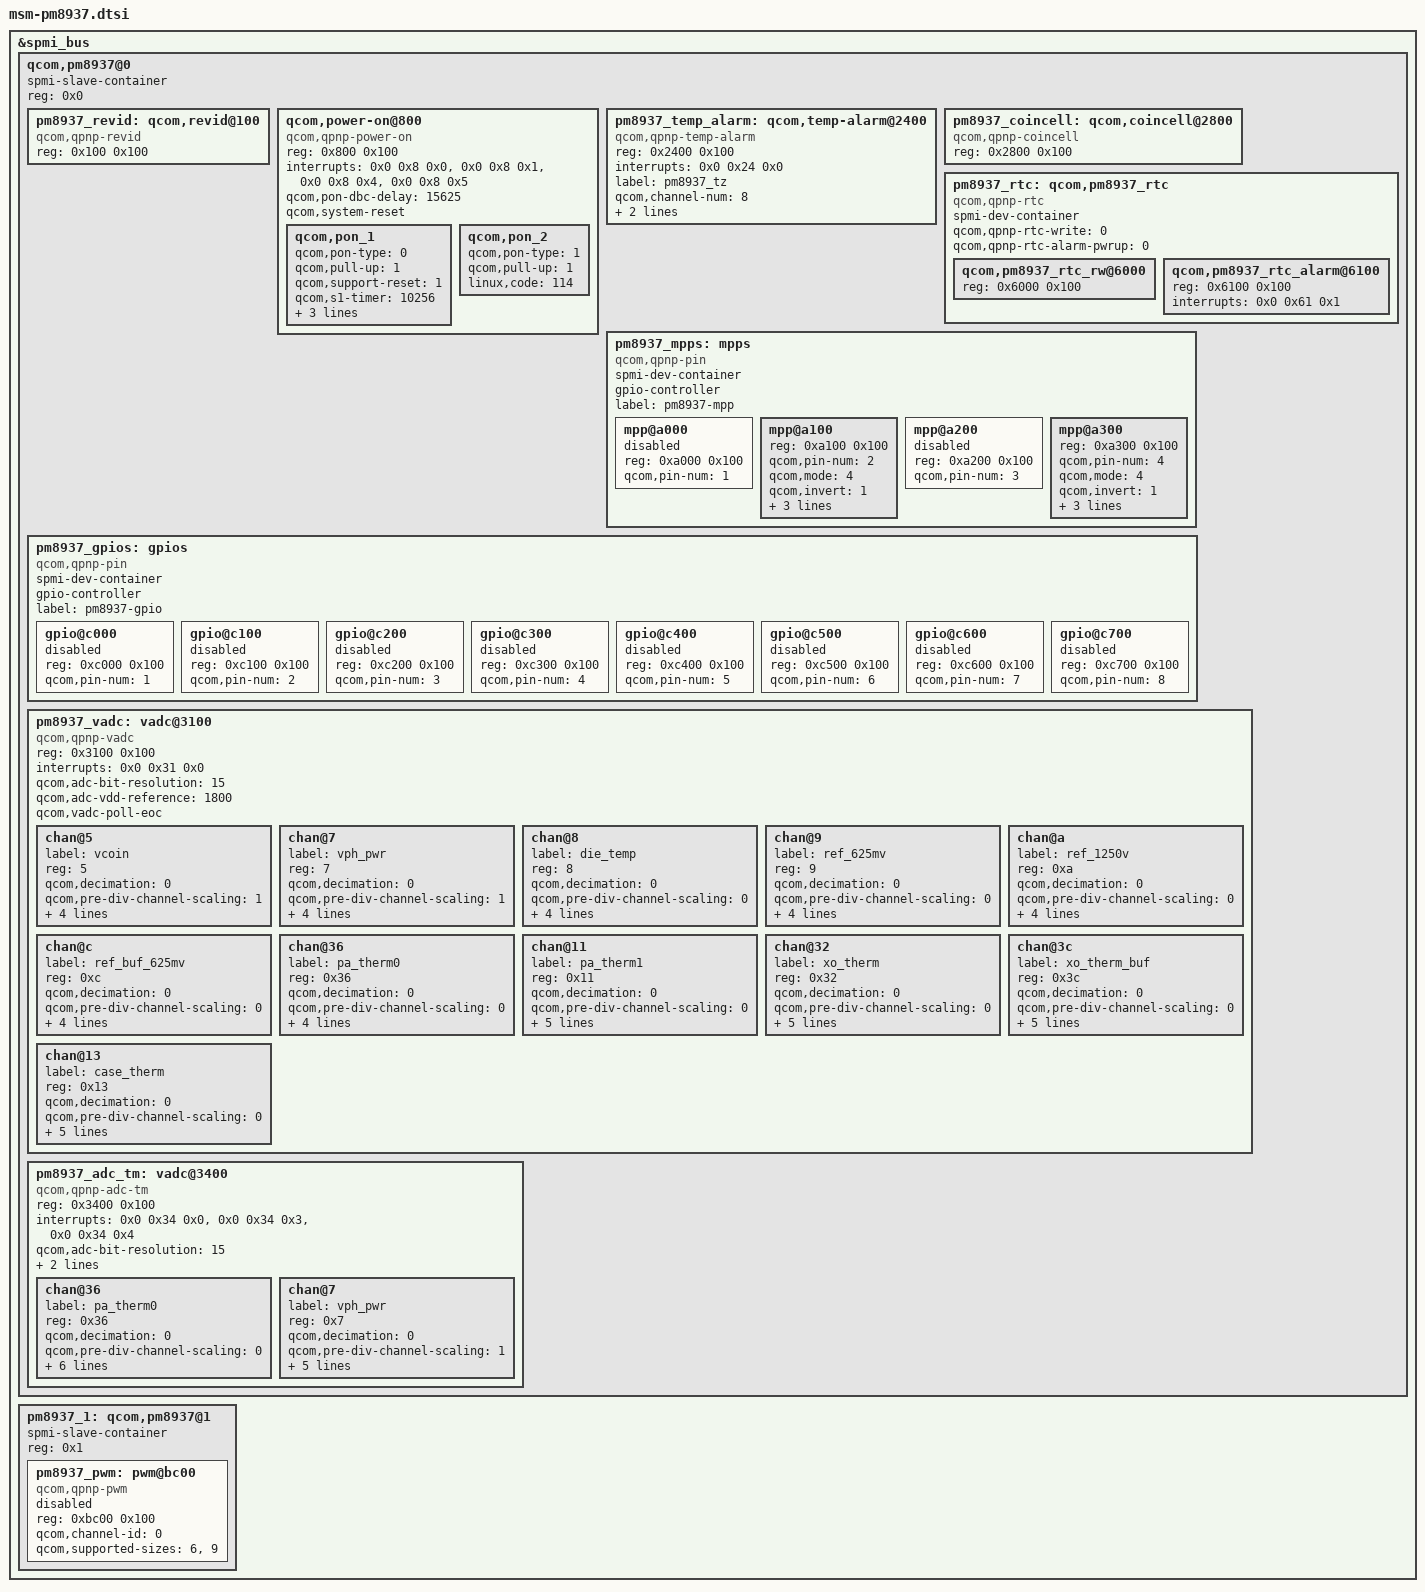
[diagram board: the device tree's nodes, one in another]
/*
 * Copyright (c) 2015-2016, The Linux Foundation. All rights reserved.
 *
 * This program is free software; you can redistribute it and/or modify
 * it under the terms of the GNU General Public License version 2 and
 * only version 2 as published by the Free Software Foundation.
 *
 * This program is distributed in the hope that it will be useful,
 * but WITHOUT ANY WARRANTY; without even the implied warranty of
 * MERCHANTABILITY or FITNESS FOR A PARTICULAR PURPOSE.  See the
 * GNU General Public License for more details.
 */

&spmi_bus {

	qcom,pm8937@0 {
		spmi-slave-container;
		reg = <0x0>;
		#address-cells = <1>;
		#size-cells = <1>;

		pm8937_revid: qcom,revid@100 {
			compatible = "qcom,qpnp-revid";
			reg = <0x100 0x100>;
		};

		qcom,power-on@800 {
			compatible = "qcom,qpnp-power-on";
			reg = <0x800 0x100>;
			interrupts = <0x0 0x8 0x0>,
				<0x0 0x8 0x1>,
				<0x0 0x8 0x4>,
				<0x0 0x8 0x5>;
			interrupt-names = "kpdpwr", "resin",
				"resin-bark", "kpdpwr-resin-bark";
			qcom,pon-dbc-delay = <15625>;
			qcom,system-reset;

			qcom,pon_1 {
				qcom,pon-type = <0>;
				qcom,pull-up = <1>;
				qcom,support-reset = <1>;
				qcom,s1-timer = <10256>;
				qcom,s2-timer = <2000>;
				qcom,s2-type = <7>;
				linux,code = <116>;
			};

			qcom,pon_2 {
				qcom,pon-type = <1>;
				qcom,pull-up = <1>;
				linux,code = <114>;
			};
		};

		pm8937_temp_alarm: qcom,temp-alarm@2400 {
			compatible = "qcom,qpnp-temp-alarm";
			reg = <0x2400 0x100>;
			interrupts = <0x0 0x24 0x0>;
			label = "pm8937_tz";
			qcom,channel-num = <8>;
			qcom,threshold-set = <0>;
			qcom,temp_alarm-vadc = <&pm8937_vadc>;
		};

		pm8937_coincell: qcom,coincell@2800 {
			compatible = "qcom,qpnp-coincell";
			reg = <0x2800 0x100>;
		};

		pm8937_rtc: qcom,pm8937_rtc {
			spmi-dev-container;
			compatible = "qcom,qpnp-rtc";
			#address-cells = <1>;
			#size-cells = <1>;
			qcom,qpnp-rtc-write = <0>;
			qcom,qpnp-rtc-alarm-pwrup = <0>;

			qcom,pm8937_rtc_rw@6000 {
				reg = <0x6000 0x100>;
			};

			qcom,pm8937_rtc_alarm@6100 {
				reg = <0x6100 0x100>;
				interrupts = <0x0 0x61 0x1>;
			};
		};

		pm8937_mpps: mpps {
			compatible = "qcom,qpnp-pin";
			spmi-dev-container;
			gpio-controller;
			#gpio-cells = <2>;
			#address-cells = <1>;
			#size-cells = <1>;
			label = "pm8937-mpp";

			mpp@a000 {
				reg = <0xa000 0x100>;
				qcom,pin-num = <1>;
				status = "disabled";
			};

			mpp@a100 {
				/* MPP2 - PA_THERM config */
				reg = <0xa100 0x100>;
				qcom,pin-num = <2>;
				qcom,mode = <4>; /* AIN input */
				qcom,invert = <1>; /* Enable MPP */
				qcom,ain-route = <1>; /* AMUX 6 */
				qcom,master-en = <1>;
				qcom,src-sel = <0>; /* Function constant */
			};

			mpp@a200 {
				reg = <0xa200 0x100>;
				qcom,pin-num = <3>;
				status = "disabled";
			};

			mpp@a300 {
				/* MPP4 - CASE_THERM config */
				reg = <0xa300 0x100>;
				qcom,pin-num = <4>;
				qcom,mode = <4>; /* AIN input */
				qcom,invert = <1>; /* Enable MPP */
				qcom,ain-route = <3>; /* AMUX 8 */
				qcom,master-en = <1>;
				qcom,src-sel = <0>; /* Function constant */
			};
		};

		pm8937_gpios: gpios {
			spmi-dev-container;
			compatible = "qcom,qpnp-pin";
			gpio-controller;
			#gpio-cells = <2>;
			#address-cells = <1>;
			#size-cells = <1>;
			label = "pm8937-gpio";

			gpio@c000 {
				reg = <0xc000 0x100>;
				qcom,pin-num = <1>;
				status = "disabled";
			};

			gpio@c100 {
				reg = <0xc100 0x100>;
				qcom,pin-num = <2>;
				status = "disabled";
			};

			gpio@c200 {
				reg = <0xc200 0x100>;
				qcom,pin-num = <3>;
				status = "disabled";
			};

			gpio@c300 {
				reg = <0xc300 0x100>;
				qcom,pin-num = <4>;
				status = "disabled";
			};

			gpio@c400 {
				reg = <0xc400 0x100>;
				qcom,pin-num = <5>;
				status = "disabled";
			};

			gpio@c500 {
				reg = <0xc500 0x100>;
				qcom,pin-num = <6>;
				status = "disabled";
			};

			gpio@c600 {
				reg = <0xc600 0x100>;
				qcom,pin-num = <7>;
				status = "disabled";
			};

			gpio@c700 {
				reg = <0xc700 0x100>;
				qcom,pin-num = <8>;
				status = "disabled";
			};
		};

		pm8937_vadc: vadc@3100 {
			compatible = "qcom,qpnp-vadc";
			reg = <0x3100 0x100>;
			#address-cells = <1>;
			#size-cells = <0>;
			interrupts = <0x0 0x31 0x0>;
			interrupt-names = "eoc-int-en-set";
			qcom,adc-bit-resolution = <15>;
			qcom,adc-vdd-reference = <1800>;
			qcom,vadc-poll-eoc;

			chan@5 {
				label = "vcoin";
				reg = <5>;
				qcom,decimation = <0>;
				qcom,pre-div-channel-scaling = <1>;
				qcom,calibration-type = "absolute";
				qcom,scale-function = <0>;
				qcom,hw-settle-time = <0>;
				qcom,fast-avg-setup = <0>;
			};

			chan@7 {
				label = "vph_pwr";
				reg = <7>;
				qcom,decimation = <0>;
				qcom,pre-div-channel-scaling = <1>;
				qcom,calibration-type = "absolute";
				qcom,scale-function = <0>;
				qcom,hw-settle-time = <0>;
				qcom,fast-avg-setup = <0>;
			};

			chan@8 {
				label = "die_temp";
				reg = <8>;
				qcom,decimation = <0>;
				qcom,pre-div-channel-scaling = <0>;
				qcom,calibration-type = "absolute";
				qcom,scale-function = <3>;
				qcom,hw-settle-time = <0>;
				qcom,fast-avg-setup = <0>;
			};

			chan@9 {
				label = "ref_625mv";
				reg = <9>;
				qcom,decimation = <0>;
				qcom,pre-div-channel-scaling = <0>;
				qcom,calibration-type = "absolute";
				qcom,scale-function = <0>;
				qcom,hw-settle-time = <0>;
				qcom,fast-avg-setup = <0>;
			};

			chan@a {
				label = "ref_1250v";
				reg = <0xa>;
				qcom,decimation = <0>;
				qcom,pre-div-channel-scaling = <0>;
				qcom,calibration-type = "absolute";
				qcom,scale-function = <0>;
				qcom,hw-settle-time = <0>;
				qcom,fast-avg-setup = <0>;
			};

			chan@c {
				label = "ref_buf_625mv";
				reg = <0xc>;
				qcom,decimation = <0>;
				qcom,pre-div-channel-scaling = <0>;
				qcom,calibration-type = "absolute";
				qcom,scale-function = <0>;
				qcom,hw-settle-time = <0>;
				qcom,fast-avg-setup = <0>;
			};

			chan@36 {
				label = "pa_therm0";
				reg = <0x36>;
				qcom,decimation = <0>;
				qcom,pre-div-channel-scaling = <0>;
				qcom,calibration-type = "ratiometric";
				qcom,scale-function = <2>;
				qcom,hw-settle-time = <2>;
				qcom,fast-avg-setup = <0>;
			};

			chan@11 {
				label = "pa_therm1";
				reg = <0x11>;
				qcom,decimation = <0>;
				qcom,pre-div-channel-scaling = <0>;
				qcom,calibration-type = "ratiometric";
				qcom,scale-function = <2>;
				qcom,hw-settle-time = <2>;
				qcom,fast-avg-setup = <0>;
				qcom,vadc-thermal-node;
			};

			chan@32 {
				label = "xo_therm";
				reg = <0x32>;
				qcom,decimation = <0>;
				qcom,pre-div-channel-scaling = <0>;
				qcom,calibration-type = "ratiometric";
				qcom,scale-function = <4>;
				qcom,hw-settle-time = <2>;
				qcom,fast-avg-setup = <0>;
				qcom,vadc-thermal-node;
			};

			chan@3c {
				label = "xo_therm_buf";
				reg = <0x3c>;
				qcom,decimation = <0>;
				qcom,pre-div-channel-scaling = <0>;
				qcom,calibration-type = "ratiometric";
				qcom,scale-function = <4>;
				qcom,hw-settle-time = <2>;
				qcom,fast-avg-setup = <0>;
				qcom,vadc-thermal-node;
			};

			chan@13 {
				label = "case_therm";
				reg = <0x13>;
				qcom,decimation = <0>;
				qcom,pre-div-channel-scaling = <0>;
				qcom,calibration-type = "ratiometric";
				qcom,scale-function = <2>;
				qcom,hw-settle-time = <2>;
				qcom,fast-avg-setup = <0>;
				qcom,vadc-thermal-node;
			};
		};

		pm8937_adc_tm: vadc@3400 {
			compatible = "qcom,qpnp-adc-tm";
			reg = <0x3400 0x100>;
			#address-cells = <1>;
			#size-cells = <0>;
			interrupts =	<0x0 0x34 0x0>,
					<0x0 0x34 0x3>,
					<0x0 0x34 0x4>;
			interrupt-names =	"eoc-int-en-set",
						"high-thr-en-set",
						"low-thr-en-set";
			qcom,adc-bit-resolution = <15>;
			qcom,adc-vdd-reference = <1800>;
			qcom,adc_tm-vadc = <&pm8937_vadc>;

			chan@36 {
				label = "pa_therm0";
				reg = <0x36>;
				qcom,decimation = <0>;
				qcom,pre-div-channel-scaling = <0>;
				qcom,calibration-type = "ratiometric";
				qcom,scale-function = <2>;
				qcom,hw-settle-time = <2>;
				qcom,fast-avg-setup = <0>;
				qcom,btm-channel-number = <0x48>;
				qcom,thermal-node;
			};

			chan@7 {
				label = "vph_pwr";
				reg = <0x7>;
				qcom,decimation = <0>;
				qcom,pre-div-channel-scaling = <1>;
				qcom,calibration-type = "absolute";
				qcom,scale-function = <0>;
				qcom,hw-settle-time = <0>;
				qcom,fast-avg-setup = <0>;
				qcom,btm-channel-number = <0x68>;
			};
		};

	};

	pm8937_1: qcom,pm8937@1 {
		spmi-slave-container;
		reg = <0x1>;
		#address-cells = <1>;
		#size-cells = <1>;

		pm8937_pwm: pwm@bc00 {
			status = "disabled";
			compatible = "qcom,qpnp-pwm";
			reg = <0xbc00 0x100>;
			reg-names = "qpnp-lpg-channel-base";
			qcom,channel-id = <0>;
			qcom,supported-sizes = <6>, <9>;
			#pwm-cells = <2>;
		};
	};
};
